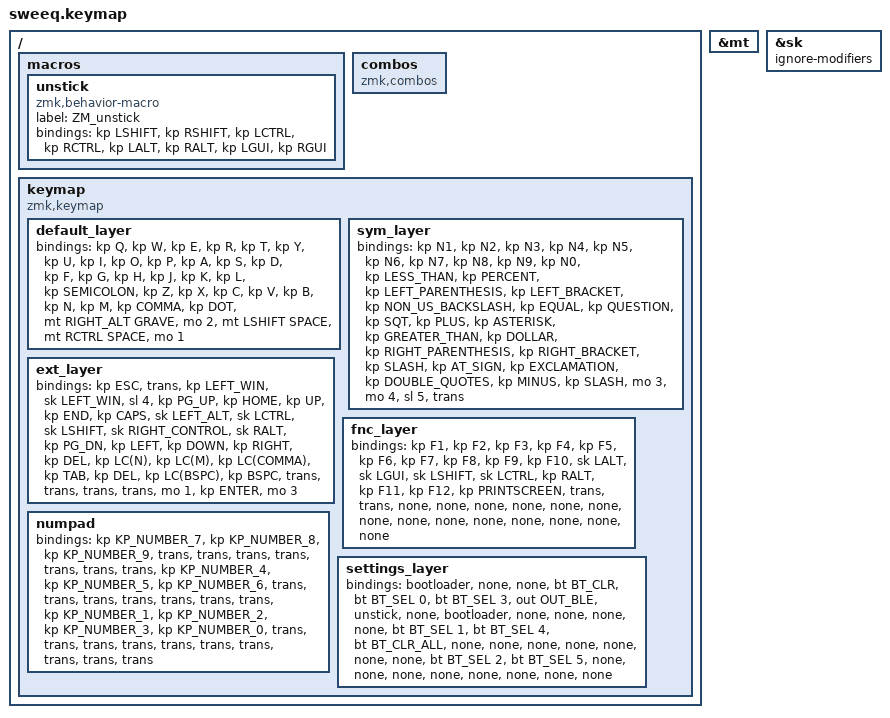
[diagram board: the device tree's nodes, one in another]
/*
 * Copyright (c) 2020 The ZMK Contributors
 *
 * SPDX-License-Identifier: MIT
 */

#include <behaviors/unicode.dtsi>
#include <behaviors.dtsi>
#include <dt-bindings/zmk/bt.h>
#include <dt-bindings/zmk/keys.h>
#include <dt-bindings/zmk/outputs.h>

// Layer definitions

#define BASE 0
#define SYM 1
#define EXT 2
#define FNC 3
#define SYM2 4
#define ACCENT 5
#define SETTINGS 6

// -----------------

&mt {
    //  flavor = "tap-preferred";
    // tapping_term_ms = <200>;
};

&sk { ignore-modifiers; };

/ {
    macros {
        // sometimes my device thinks a modifier is being held down
        // pressing all modifiers fixes it.

        unstick: unstick {
            label = "ZM_unstick";
            compatible = "zmk,behavior-macro";
            #binding-cells = <0>;
            bindings = <&kp LSHIFT &kp RSHIFT &kp LCTRL &kp RCTRL &kp LALT &kp RALT &kp LGUI &kp RGUI>;
        };
    };

    combos {
        compatible = "zmk,combos";

        // both right thumb keys
        // internal-left & external-right thumb keys
        // both left thumb keys
    };

    keymap {
        compatible = "zmk,keymap";

        // Base alpha layer

        default_layer {
            bindings = <
&kp Q  &kp W  &kp E  &kp R  &kp T  &kp Y  &kp U  &kp I  &kp O  &kp P  &kp A  &kp S  &kp D  &kp F  &kp G  &kp H  &kp J  &kp K  &kp L  &kp SEMICOLON  &kp Z  &kp X  &kp C  &kp V  &kp B  &kp N  &kp M  &kp COMMA  &kp DOT  &mt RIGHT_ALT GRAVE  &mo 2  &mt LSHIFT SPACE  &mt RCTRL SPACE  &mo 1
            >;
        };

        sym_layer {
            bindings = <
&kp N1  &kp N2  &kp N3  &kp N4  &kp N5  &kp N6  &kp N7  &kp N8  &kp N9  &kp N0  &kp LESS_THAN  &kp PERCENT  &kp LEFT_PARENTHESIS  &kp LEFT_BRACKET  &kp NON_US_BACKSLASH  &kp EQUAL  &kp QUESTION  &kp SQT  &kp PLUS  &kp ASTERISK  &kp GREATER_THAN  &kp DOLLAR  &kp RIGHT_PARENTHESIS  &kp RIGHT_BRACKET  &kp SLASH  &kp AT_SIGN  &kp EXCLAMATION  &kp DOUBLE_QUOTES  &kp MINUS  &kp SLASH  &mo 3  &mo 4  &sl 5  &trans
            >;
        };

        ext_layer {
            bindings = <
&kp ESC  &trans  &kp LEFT_WIN  &sk LEFT_WIN  &sl 4  &kp PG_UP  &kp HOME  &kp UP  &kp END  &kp CAPS  &sk LEFT_ALT  &sk LCTRL  &sk LSHIFT  &sk RIGHT_CONTROL  &sk RALT  &kp PG_DN  &kp LEFT  &kp DOWN  &kp RIGHT  &kp DEL  &kp LC(N)  &kp LC(M)  &kp LC(COMMA)  &kp TAB  &kp DEL  &kp LC(BSPC)  &kp BSPC  &trans  &trans  &trans  &trans  &mo 1  &kp ENTER  &mo 3
            >;
        };

        fnc_layer {
            bindings = <
&kp F1  &kp F2  &kp F3  &kp F4  &kp F5  &kp F6  &kp F7  &kp F8  &kp F9  &kp F10  &sk LALT  &sk LGUI  &sk LSHIFT  &sk LCTRL  &kp RALT  &kp F11  &kp F12  &kp PRINTSCREEN  &trans  &trans  &none  &none  &none  &none  &none  &none  &none  &none  &none  &none  &none  &none  &none  &none
            >;
        };

        numpad {
            bindings = <
&kp KP_NUMBER_7  &kp KP_NUMBER_8  &kp KP_NUMBER_9  &trans  &trans  &trans  &trans  &trans  &trans  &trans  &kp KP_NUMBER_4  &kp KP_NUMBER_5  &kp KP_NUMBER_6  &trans  &trans  &trans  &trans  &trans  &trans  &trans  &kp KP_NUMBER_1  &kp KP_NUMBER_2  &kp KP_NUMBER_3  &kp KP_NUMBER_0  &trans  &trans  &trans  &trans  &trans  &trans  &trans  &trans  &trans  &trans
            >;
        };

        settings_layer {
            bindings = <
&bootloader  &none  &none  &bt BT_CLR  &bt BT_SEL 0  &bt BT_SEL 3  &out OUT_BLE  &unstick  &none  &bootloader  &none  &none  &none  &none  &bt BT_SEL 1  &bt BT_SEL 4  &bt BT_CLR_ALL  &none  &none  &none  &none  &none  &none  &none  &bt BT_SEL 2  &bt BT_SEL 5  &none  &none  &none  &none  &none  &none  &none  &none
            >;
        };
    };
};
